# CY8C3245AXI_158 register map
File version: 0.1
CY8C32
Registers are 8-bit, read-write, no defined reset value unless marked. A register's access mark holds for its fields unless they carry their own. Offsets are from the block's base; lines under a group give offsets from that group; [hi:lo] are bit positions; {n}, {i} and the like mark numbered series; 'fields as' and 'values as' point back to an identical list; <NAME> marks a mode.

## Memory map
0x000043AA ADC_DelSig_1 size 0x17E0
0x00006421 PWM_1 size 0x71
0x00006424 LIN_1_UART size 0x145 — UART
0x00006426 LIN_1 size 0x151
0x00006440 UART_1 size 0x21 — UART
0x00006528 PWM_2 size 0x71

## UART_1 — UART
Base 0x00006440
0x00 TX_UART_1_TX_DATA — TX Data Register
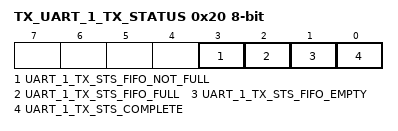
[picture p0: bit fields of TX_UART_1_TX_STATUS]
0x20 TX_UART_1_TX_STATUS — TX status register
  [3] UART_1_TX_STS_FIFO_NOT_FULL ro, [2] UART_1_TX_STS_FIFO_FULL ro, [1] UART_1_TX_STS_FIFO_EMPTY ro, [0] UART_1_TX_STS_COMPLETE ro

## LIN_1
Base 0x00006426
0x00 INACT_INACTIVITY_DIV0_REG — Bus Inactivity Divider 0 Register
  [7:0] LIN_1_INACTIVITY_DIV0 — ((Baud Rate * 16 (oversampling) / 10 (100 ms)) / 256) - 1
0x01 BREAK_THRESHOLD_REG — Break Threshold Register
  [7:0] LIN_1_BREAK_THRESHOLD — Break threshold detection value assuming 16x oversampling
0x10 INACT_INACTIVITY_DIV1_REG — Bus Inactivity Divider 1 Register
  [7:0] LIN_1_INACTIVITY_DIV1 — (Baud Rate * 16 (oversampling) / 10 (100 ms)) % 256
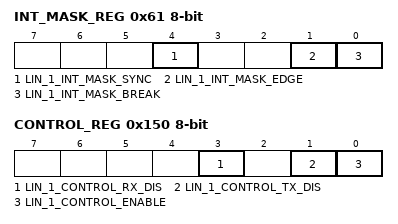
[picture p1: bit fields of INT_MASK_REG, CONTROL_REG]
0x61 INT_MASK_REG — Status Mask Register
  [4] LIN_1_INT_MASK_SYNC — Sync field detected mask
  [1] LIN_1_INT_MASK_EDGE — Edge detected mask
  [0] LIN_1_INT_MASK_BREAK — Break field threshold detected mask
0x150 CONTROL_REG — Control Register
  [3] LIN_1_CONTROL_RX_DIS — Disconnect RX from LIN bus
  [1] LIN_1_CONTROL_TX_DIS — Force TX pin low
  [0] LIN_1_CONTROL_ENABLE — Enable base LIN operation

## LIN_1_UART — UART
Base 0x00006424
0x00 RX_LIN_1_UART_RX_ADDRESS1 — RX Address1 Register
0x10 RX_LIN_1_UART_RX_ADDRESS2 — RX Address2 Register
0x20 RX_LIN_1_UART_RX_DATA — RX Data Register
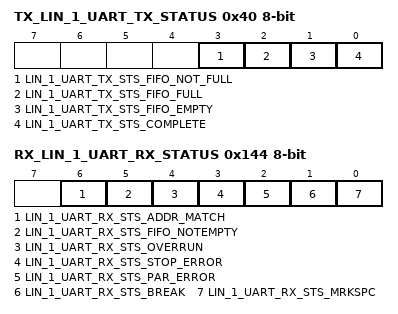
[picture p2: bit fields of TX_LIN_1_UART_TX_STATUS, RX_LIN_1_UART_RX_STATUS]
0x40 TX_LIN_1_UART_TX_STATUS — TX status register
  [3] LIN_1_UART_TX_STS_FIFO_NOT_FULL ro, [2] LIN_1_UART_TX_STS_FIFO_FULL ro, [1] LIN_1_UART_TX_STS_FIFO_EMPTY ro, [0] LIN_1_UART_TX_STS_COMPLETE ro
0x122 TX_LIN_1_UART_TX_DATA — TX Data Register
0x144 RX_LIN_1_UART_RX_STATUS — RX status register
  [6] LIN_1_UART_RX_STS_ADDR_MATCH ro, [5] LIN_1_UART_RX_STS_FIFO_NOTEMPTY ro, [4] LIN_1_UART_RX_STS_OVERRUN ro, [3] LIN_1_UART_RX_STS_STOP_ERROR ro, [2] LIN_1_UART_RX_STS_PAR_ERROR ro, [1] LIN_1_UART_RX_STS_BREAK ro, [0] LIN_1_UART_RX_STS_MRKSPC ro

## PWM_1
Base 0x00006421
0x00 PWM_1__COMPARE1 — UDB.D0 - Assigned Compare1 Value
0x10 PWM_1__COMPARE2 — UDB.D1 - Assigned Compare2 Value
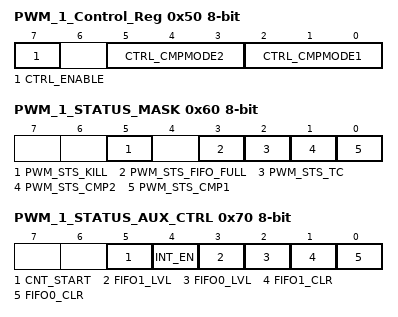
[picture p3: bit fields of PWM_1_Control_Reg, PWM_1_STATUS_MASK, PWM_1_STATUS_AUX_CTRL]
0x50 PWM_1_Control_Reg — UDB Control Register - Assigned Control Register Value
  [7] CTRL_ENABLE — Enable the PWM
  [5:3] CTRL_CMPMODE2 — Compare mode 2
  [2:0] CTRL_CMPMODE1 — Compare mode 1
0x60 PWM_1_STATUS_MASK — UDB Status bits Interrupt Mask Enable Register
  [5] PWM_STS_KILL ro — Enables the Interrupt on Kill
  [3] PWM_STS_FIFO_FULL ro — FIFO Full Status Mask
  [2] PWM_STS_TC ro — Enables the Interrupt on Terminal Count
  [1] PWM_STS_CMP2 ro — Enables the Interrupt on Compare 2
  [0] PWM_STS_CMP1 ro — Enables the Interrupt on Compare 1
0x70 PWM_1_STATUS_AUX_CTRL — UDB Auxilliary Control Register
  [5] CNT_START — FIFO0 clear
    0=E_CNT_START0 (Disable counter); 1=E_CNT_START1 (Enable counter)
  [4] INT_EN
    0=E_INT_EN0 (Interrupt disabled); 1=E_INT_EN1 (Interrupt enabled)
  [3] FIFO1_LVL — FIFO level
    0=E_FIFO_LVL_0 (FIFO LVL: input mode: FIFO not full; output mode: FIFO not empty); 1=E_FIFO_LVL_1 (FIFO LVL: input mode: FIFO at least 1/2 empty; output mode: FIFO at least 1/2 full)
  [2] FIFO0_LVL — FIFO level
    values as FIFO1_LVL
  [1] FIFO1_CLR — FIFO1 clear
    0=E_FIFO_CLR_0 (Normal FIFO operation); 1=E_FIFO_CLR_1 (Clear FIFO state)
  [0] FIFO0_CLR — FIFO0 clear
    values as FIFO1_CLR

## PWM_2
Base 0x00006528
Registers as PWM_1 (with PWM_1 read as PWM_2), without PWM_1_Control_Reg, PWM_1_STATUS_MASK; these are added or differ:
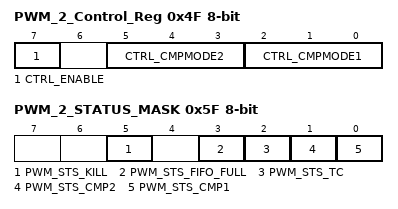
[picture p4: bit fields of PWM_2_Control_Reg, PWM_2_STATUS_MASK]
0x4F PWM_2_Control_Reg — UDB Control Register - Assigned Control Register Value
  [7] CTRL_ENABLE — Enable the PWM
  [5:3] CTRL_CMPMODE2 — Compare mode 2
  [2:0] CTRL_CMPMODE1 — Compare mode 1
0x5F PWM_2_STATUS_MASK — UDB Status bits Interrupt Mask Enable Register
  fields as PWM_1.PWM_1_STATUS_MASK
